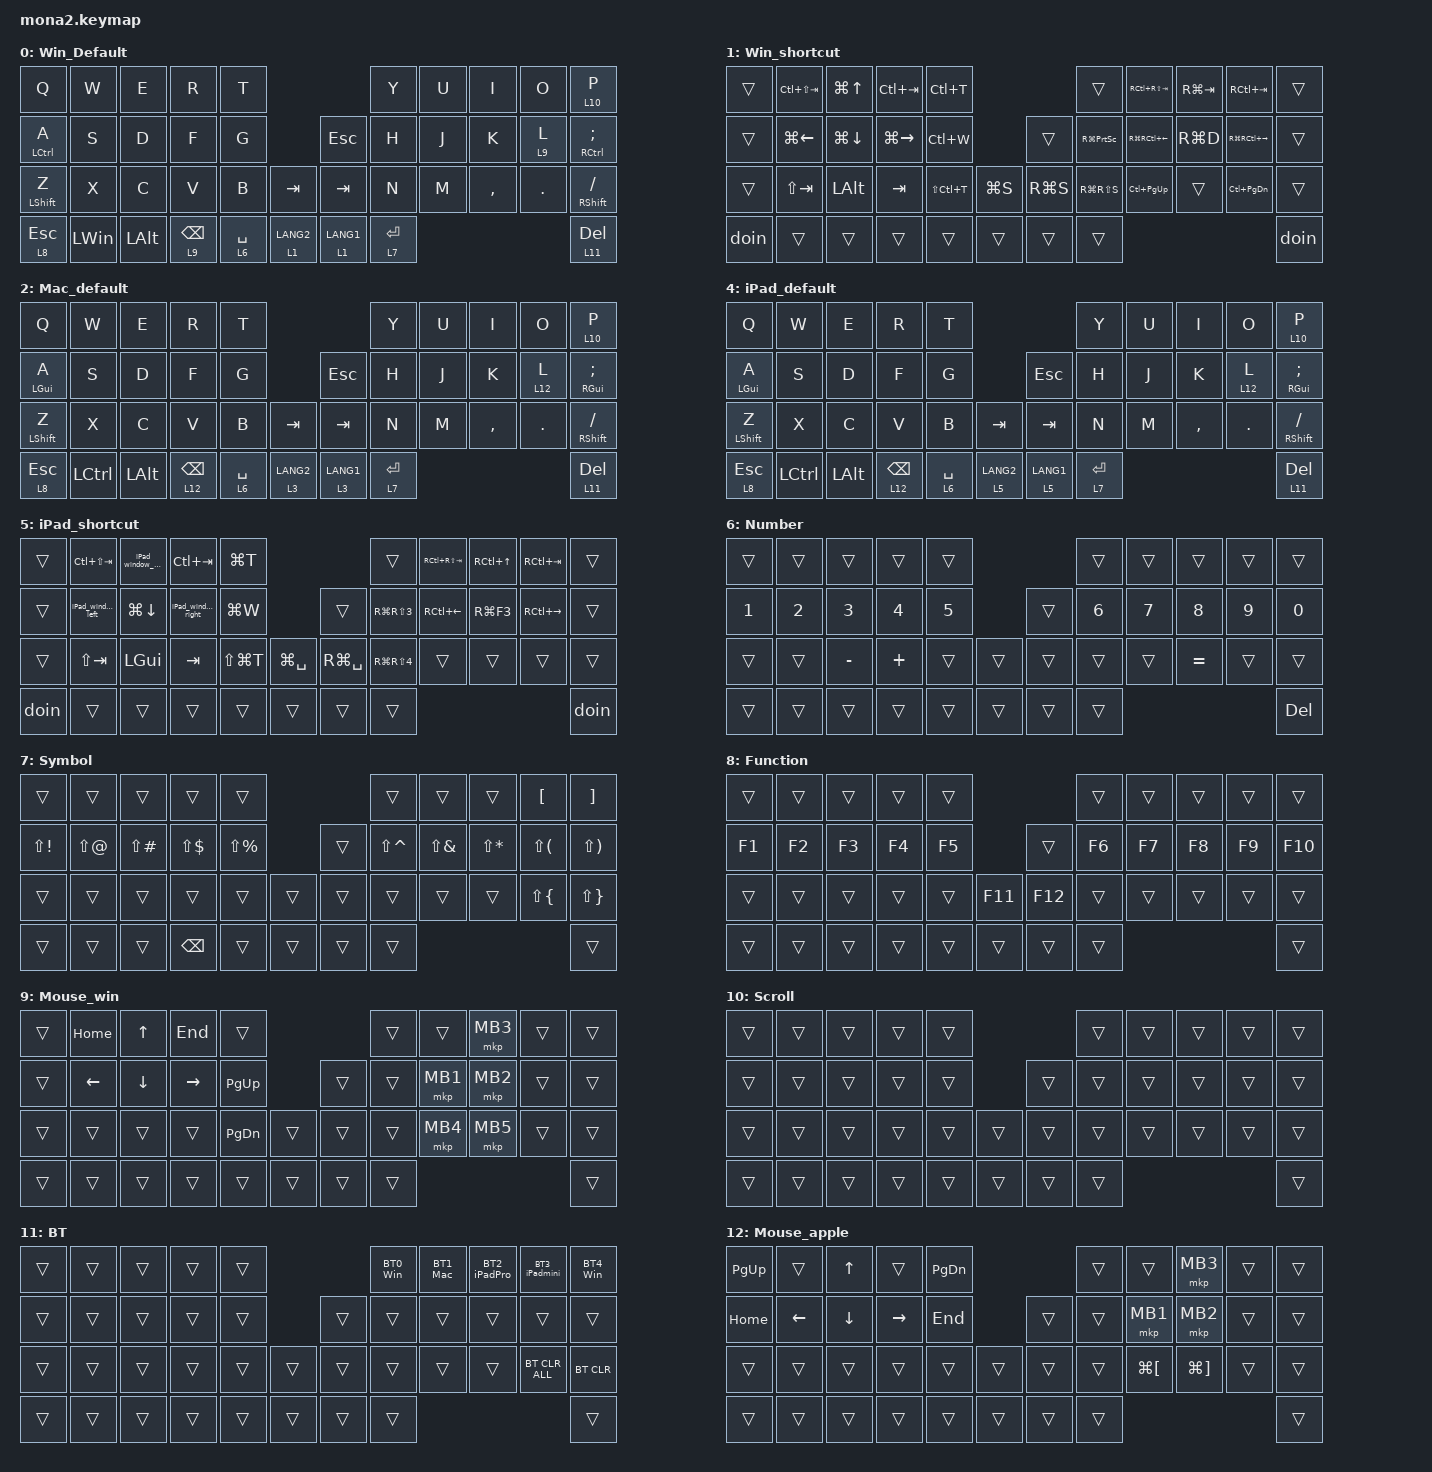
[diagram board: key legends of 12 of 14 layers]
#include <input/processors.dtsi>
#include <dt-bindings/zmk/input_transform.h>
#include <zephyr/dt-bindings/input/input-event-codes.h>
#include <behaviors.dtsi>
#include <dt-bindings/zmk/bt.h>
#include <dt-bindings/zmk/keys.h>
#include <dt-bindings/zmk/pointing.h>

#define ZMK_POINTING_DEFAULT_SCRL_VAL 100
#define MOUSE 9
#define SCROLL 10

&mt {
    flavor = "balanced";
    quick-tap-ms = <0>;
};

&lt {
    quick-tap-ms = <300>;
    flavor = "balanced";
};

/ {
    combos {
        compatible = "zmk,combos";

        quotation {
            bindings = <&kp SINGLE_QUOTE>;
            key-positions = <20 19>;
        };

        minus {
            bindings = <&kp MINUS>;
            key-positions = <9 8>;
        };

        Tab {
            bindings = <&kp TAB>;
            key-positions = <18 19>;
        };

        equaol {
            bindings = <&kp EQUAL>;
            key-positions = <30 29>;
        };

        tenky {
            bindings = <&tog 13>;
            key-positions = <7 9 8>;
        };
    };

    macros {
        BT0_Win: BT0_Win {
            compatible = "zmk,behavior-macro";
            #binding-cells = <0>;
            bindings = <&bt BT_SEL 0>, <&macro_wait_time 200>, <&to 0>;

            label = "BT0_WIN";
        };

        BT1_Mac: BT1_Mac {
            compatible = "zmk,behavior-macro";
            #binding-cells = <0>;
            bindings = <&bt BT_SEL 1>, <&macro_wait_time 200>, <&to 2>;

            label = "BT1_MAC";
        };

        BT2_iPadPro: BT2_iPadpro {
            compatible = "zmk,behavior-macro";
            #binding-cells = <0>;
            bindings = <&bt BT_SEL 2>, <&macro_wait_time 200>, <&to 4>;

            label = "BT2_IPADPRO";
        };

        BT3_iPadmini: BT3_iPadmini {
            compatible = "zmk,behavior-macro";
            #binding-cells = <0>;
            bindings = <&bt BT_SEL 3>, <&macro_wait_time 200>, <&to 4>;

            label = "BT3_IPADMINI";
        };

        BT4_Win: BT4_Win {
            compatible = "zmk,behavior-macro";
            #binding-cells = <0>;
            bindings = <&bt BT_SEL 4>, <&macro_wait_time 200>, <&to 0>;

            label = "BT4_WIN";
        };

        doin: doin {
            compatible = "zmk,behavior-macro";
            #binding-cells = <0>;
            bindings =
                <&macro_tap>,
                <&kp D &kp O &kp I &kp N &kp B &kp O &kp NUMBER_1 &kp N0>;

            label = "DOIN";
        };

        iPad_window_left: iPad_window_left {
            compatible = "zmk,behavior-macro";
            #binding-cells = <0>;
            bindings =
                <&macro_press>,
                <&kp LCTRL &kp CAPSLOCK>,
                <&macro_tap>,
                <&kp LEFT_ARROW>,
                <&macro_release>,
                <&kp LCTRL &kp CAPS>;

            label = "IPAD_WINDOW_LEFT";
        };

        iPad_window_right: iPad_window_right {
            compatible = "zmk,behavior-macro";
            #binding-cells = <0>;
            bindings =
                <&macro_press>,
                <&kp LCTRL &kp CAPSLOCK>,
                <&macro_tap>,
                <&kp RIGHT>,
                <&macro_release>,
                <&kp LCTRL &kp CAPS>;

            label = "IPAD_WINDOW_RIGHT";
        };

        iPad_window_max: iPad_window_max {
            compatible = "zmk,behavior-macro";
            #binding-cells = <0>;
            bindings =
                <&macro_press>,
                <&kp CAPSLOCK>,
                <&macro_tap>,
                <&kp F>,
                <&macro_release>,
                <&kp CAPS>;

            label = "IPAD_WINDOW_MAX";
        };

        iPad_taskview: iPad_taskview {
            compatible = "zmk,behavior-macro";
            #binding-cells = <0>;
            bindings =
                <&macro_press>,
                <&kp CAPSLOCK>,
                <&macro_tap>,
                <&kp UP_ARROW>,
                <&macro_release>,
                <&kp CAPS>;

            label = "IPAD_TASKVIEW";
        };
    };

    behaviors {
        scroll_up_down: mouse_wheel_up_down {
            compatible = "zmk,behavior-sensor-rotate";
            #sensor-binding-cells = <0>;
            bindings = <&msc SCRL_UP>, <&msc SCRL_DOWN>;

            tap-ms = <20>;
        };

        scroll_right_left: mouse_wheel_right_left {
            compatible = "zmk,behavior-sensor-rotate";
            #sensor-binding-cells = <0>;
            bindings = <&msc SCRL_LEFT>, <&msc SCRL_RIGHT>;

            tap-ms = <20>;
        };
    };

    keymap {
        compatible = "zmk,keymap";

        Win_Default {
            bindings = <
&kp Q             &kp W         &kp E         &kp R            &kp T                                    &kp Y        &kp U  &kp I      &kp O    &lt 10 P
&mt LCTRL A       &kp S         &kp D         &kp F            &kp G                       &kp ESCAPE   &kp H        &kp J  &kp K      &lt 9 L  &mt RCTRL SEMICOLON
&mt LEFT_SHIFT Z  &kp X         &kp C         &kp V            &kp B        &kp TAB        &kp TAB      &kp N        &kp M  &kp COMMA  &kp DOT  &mt RIGHT_SHIFT SLASH
&lt 8 ESCAPE      &kp LEFT_WIN  &kp LEFT_ALT  &lt 9 BACKSPACE  &lt 6 SPACE  &lt 1 LANG2    &lt 1 LANG1  &lt 7 ENTER                             &lt 11 DELETE
            >;

            sensor-bindings = <&scroll_up_down>;
        };

        Win_shortcut {
            bindings = <
&trans  &kp LC(LS(TAB))     &kp LG(UP_ARROW)    &kp LC(TAB)    &kp LC(T)                              &trans               &kp RC(RS(TAB))         &kp RG(TAB)  &kp RC(TAB)        &trans
&trans  &kp LG(LEFT_ARROW)  &kp LG(DOWN_ARROW)  &kp LG(RIGHT)  &kp LC(W)                   &trans     &kp RG(PRINTSCREEN)  &kp RG(RC(LEFT_ARROW))  &kp RG(D)    &kp RG(RC(RIGHT))  &trans
&trans  &kp LS(TAB)         &kp LALT            &kp TAB        &kp LS(LC(T))  &kp LG(S)    &kp RG(S)  &kp RG(RS(S))        &kp LC(PG_UP)           &trans       &kp LC(PAGE_DOWN)  &trans
&doin   &trans              &trans              &trans         &trans         &trans       &trans     &trans                                                                       &doin
            >;

            sensor-bindings = <&inc_dec_kp LC(PG_UP) LC(PAGE_DOWN)>;
        };

        Mac_default {
            bindings = <
&kp Q             &kp W      &kp E         &kp R             &kp T                                    &kp Y        &kp U  &kp I      &kp O     &lt 10 P
&mt LEFT_GUI A    &kp S      &kp D         &kp F             &kp G                       &kp ESCAPE   &kp H        &kp J  &kp K      &lt 12 L  &mt RIGHT_GUI SEMICOLON
&mt LEFT_SHIFT Z  &kp X      &kp C         &kp V             &kp B        &kp TAB        &kp TAB      &kp N        &kp M  &kp COMMA  &kp DOT   &mt RIGHT_SHIFT SLASH
&lt 8 ESCAPE      &kp LCTRL  &kp LEFT_ALT  &lt 12 BACKSPACE  &lt 6 SPACE  &lt 3 LANG2    &lt 3 LANG1  &lt 7 ENTER                              &lt 11 DELETE
            >;

            sensor-bindings = <&scroll_up_down>;
        };

        Mac_shortcut {
            bindings = <
&trans  &kp LC(LS(TAB))             &kp LG(LC(F))       &kp LC(TAB)            &kp LG(T)                                      &trans                &kp RS(TAB)         &kp LC(UP_ARROW)  &kp RC(TAB)    &trans
&trans  &kp LG(LC(LA(LEFT_ARROW)))  &kp LG(DOWN_ARROW)  &kp LG(LC(LA(RIGHT)))  &kp LG(W)                       &trans         &kp RG(RS(NUMBER_3))  &kp LC(LEFT_ARROW)  &kp RG(F3)        &kp LC(RIGHT)  &trans
&trans  &kp LS(TAB)                 &kp LEFT_GUI        &kp TAB                &kp LS(LG(T))  &kp LG(SPACE)    &kp RG(SPACE)  &kp RG(RS(NUMBER_4))  &trans              &trans            &trans         &trans
&doin   &trans                      &trans              &trans                 &trans         &trans           &trans         &trans                                                                     &doin
            >;

            sensor-bindings = <&inc_dec_kp LA(RIGHT) LC(LEFT)>;
        };

        iPad_default {
            bindings = <
&kp Q             &kp W      &kp E         &kp R             &kp T                                    &kp Y        &kp U  &kp I      &kp O     &lt 10 P
&mt LEFT_GUI A    &kp S      &kp D         &kp F             &kp G                       &kp ESCAPE   &kp H        &kp J  &kp K      &lt 12 L  &mt RIGHT_GUI SEMICOLON
&mt LEFT_SHIFT Z  &kp X      &kp C         &kp V             &kp B        &kp TAB        &kp TAB      &kp N        &kp M  &kp COMMA  &kp DOT   &mt RIGHT_SHIFT SLASH
&lt 8 ESCAPE      &kp LCTRL  &kp LEFT_ALT  &lt 12 BACKSPACE  &lt 6 SPACE  &lt 5 LANG2    &lt 5 LANG1  &lt 7 ENTER                              &lt 11 DELETE
            >;

            sensor-bindings = <&scroll_up_down>;
        };

        iPad_shortcut {
            bindings = <
&trans  &kp LC(LS(TAB))    &iPad_window_max    &kp LC(TAB)         &kp LG(T)                                      &trans                &kp RC(RS(TAB))     &kp RC(UP_ARROW)  &kp RC(TAB)    &trans
&trans  &iPad_window_left  &kp LG(DOWN_ARROW)  &iPad_window_right  &kp LG(W)                       &trans         &kp RG(RS(NUMBER_3))  &kp RC(LEFT_ARROW)  &kp RG(F3)        &kp RC(RIGHT)  &trans
&trans  &kp LS(TAB)        &kp LEFT_GUI        &kp TAB             &kp LS(LG(T))  &kp LG(SPACE)    &kp RG(SPACE)  &kp RG(RS(NUMBER_4))  &trans              &trans            &trans         &trans
&doin   &trans             &trans              &trans              &trans         &trans           &trans         &trans                                                                     &doin
            >;

            sensor-bindings = <&inc_dec_kp LA(RIGHT) LC(LEFT)>;
        };

        Number {
            bindings = <
&trans  &trans  &trans     &trans    &trans                    &trans  &trans  &trans     &trans  &trans
&kp N1  &kp N2  &kp N3     &kp N4    &kp N5            &trans  &kp N6  &kp N7  &kp N8     &kp N9  &kp N0
&trans  &trans  &kp MINUS  &kp PLUS  &trans  &trans    &trans  &trans  &trans  &kp EQUAL  &trans  &trans
&trans  &trans  &trans     &trans    &trans  &trans    &trans  &trans                             &kp DEL
            >;

            sensor-bindings = <&inc_dec_kp C_VOLUME_DOWN C_VOLUME_UP>;
        };

        Symbol {
            bindings = <
&trans        &trans      &trans         &trans         &trans                           &trans         &trans        &trans        &kp LBKT      &kp RBKT
&kp LS(EXCL)  &kp LS(AT)  &kp LS(POUND)  &kp LS(DLLR)   &kp LS(PRCNT)            &trans  &kp LS(CARET)  &kp LS(AMPS)  &kp LS(STAR)  &kp LS(LPAR)  &kp LS(RPAR)
&trans        &trans      &trans         &trans         &trans         &trans    &trans  &trans         &trans        &trans        &kp LS(LBRC)  &kp LS(RBRC)
&trans        &trans      &trans         &kp BACKSPACE  &trans         &trans    &trans  &trans                                                   &trans
            >;

            sensor-bindings = <&scroll_up_down>;
        };

        Function {
            bindings = <
&trans  &trans  &trans  &trans  &trans                      &trans  &trans  &trans  &trans  &trans
&kp F1  &kp F2  &kp F3  &kp F4  &kp F5             &trans   &kp F6  &kp F7  &kp F8  &kp F9  &kp F10
&trans  &trans  &trans  &trans  &trans  &kp F11    &kp F12  &trans  &trans  &trans  &trans  &trans
&trans  &trans  &trans  &trans  &trans  &trans     &trans   &trans                          &trans
            >;

            sensor-bindings = <&scroll_up_down>;
        };

        Mouse_win {
            bindings = <
&trans  &kp HOME        &kp UP_ARROW    &kp END          &trans                           &trans  &trans    &mkp MB3  &trans  &trans
&trans  &kp LEFT_ARROW  &kp DOWN_ARROW  &kp RIGHT_ARROW  &kp PG_UP                &trans  &trans  &mkp MB1  &mkp MB2  &trans  &trans
&trans  &trans          &trans          &trans           &kp PAGE_DOWN  &trans    &trans  &trans  &mkp MB4  &mkp MB5  &trans  &trans
&trans  &trans          &trans          &trans           &trans         &trans    &trans  &trans                              &trans
            >;
        };

        Scroll {
            bindings = <
&trans  &trans  &trans  &trans  &trans                    &trans  &trans  &trans  &trans  &trans
&trans  &trans  &trans  &trans  &trans            &trans  &trans  &trans  &trans  &trans  &trans
&trans  &trans  &trans  &trans  &trans  &trans    &trans  &trans  &trans  &trans  &trans  &trans
&trans  &trans  &trans  &trans  &trans  &trans    &trans  &trans                          &trans
            >;
        };

        BT {
            bindings = <
&trans  &trans  &trans  &trans  &trans                    &BT0_Win  &BT1_Mac  &BT2_iPadPro  &BT3_iPadmini   &BT4_Win
&trans  &trans  &trans  &trans  &trans            &trans  &trans    &trans    &trans        &trans          &trans
&trans  &trans  &trans  &trans  &trans  &trans    &trans  &trans    &trans    &trans        &bt BT_CLR_ALL  &bt BT_CLR
&trans  &trans  &trans  &trans  &trans  &trans    &trans  &trans                                            &trans
            >;
        };

        Mouse_apple {
            bindings = <
&kp PAGE_UP  &trans          &kp UP_ARROW    &trans           &kp PAGE_DOWN                    &trans  &trans                &mkp MB3               &trans  &trans
&kp HOME     &kp LEFT_ARROW  &kp DOWN_ARROW  &kp RIGHT_ARROW  &kp END                  &trans  &trans  &mkp MB1              &mkp MB2               &trans  &trans
&trans       &trans          &trans          &trans           &trans         &trans    &trans  &trans  &kp LG(LEFT_BRACKET)  &kp LG(RIGHT_BRACKET)  &trans  &trans
&trans       &trans          &trans          &trans           &trans         &trans    &trans  &trans                                                       &trans
            >;
        };

        tenky {
            bindings = <
&trans  &trans  &trans  &trans  &trans                       &trans        &kp N7        &kp N8        &kp N9        &kp NUMBER_0
&trans  &trans  &trans  &trans  &trans            &kp PLUS   &kp ASTERISK  &kp N4        &kp N5        &kp NUMBER_6  &kp EQUAL
&trans  &trans  &trans  &trans  &trans  &trans    &kp MINUS  &kp SLASH     &kp NUMBER_1  &kp NUMBER_2  &kp NUMBER_3  &trans
&trans  &trans  &trans  &trans  &trans  &trans    &trans     &trans                                                  &trans
            >;
        };
    };
};
